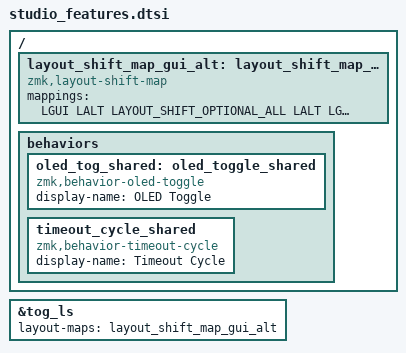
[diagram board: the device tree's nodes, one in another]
/*
 * Shared Studio/runtime feature layer.
 * Board-specific keymaps remain independent.
 *
 * Public devicetree contract:
 *   layout_shift_map_gui_alt
 *
 * Keep this label stable for firmware modules. The node name may retain an
 * implementation-specific suffix such as "_shared"; consumers must use the
 * public label, never the node name.
 */
#include <layout_shift_kp_override.dtsi>
#include <dt-bindings/zmk/layout_shift.h>
#include "personal_hold_tap.dtsi"

/ {
    layout_shift_map_gui_alt: layout_shift_map_gui_alt_shared {
        compatible = "zmk,layout-shift-map";
        mappings = <
            LGUI LALT LAYOUT_SHIFT_OPTIONAL_ALL
            LALT LGUI LAYOUT_SHIFT_OPTIONAL_ALL
            RGUI RALT LAYOUT_SHIFT_OPTIONAL_ALL
            RALT RGUI LAYOUT_SHIFT_OPTIONAL_ALL
        >;
    };

    behaviors {
        oled_tog_shared: oled_toggle_shared {
            compatible = "zmk,behavior-oled-toggle";
            #binding-cells = <0>;
            display-name = "OLED Toggle";
        };

        timeout_cycle_shared: timeout_cycle_shared {
            compatible = "zmk,behavior-timeout-cycle";
            #binding-cells = <1>;
            display-name = "Timeout Cycle";
        };
    };
};

&tog_ls {
    layout-maps = <&layout_shift_map_gui_alt>;
};

